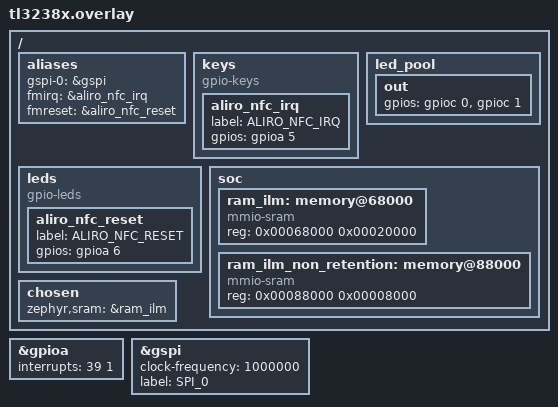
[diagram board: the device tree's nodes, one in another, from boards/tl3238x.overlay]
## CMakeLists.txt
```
#
#    Copyright (c) 2023-2024 Project CHIP Authors
#
#    Licensed under the Apache License, Version 2.0 (the "License");
#    you may not use this file except in compliance with the License.
#    You may obtain a copy of the License at
#
#        http://www.apache.org/licenses/LICENSE-2.0
#
#    Unless required by applicable law or agreed to in writing, software
#    distributed under the License is distributed on an "AS IS" BASIS,
#    WITHOUT WARRANTIES OR CONDITIONS OF ANY KIND, either express or implied.
#    See the License for the specific language governing permissions and
#    limitations under the License.
#

cmake_minimum_required(VERSION 3.20)

if(POLICY CMP0135)
  cmake_policy(SET CMP0135 NEW)
endif()

include(FetchContent)

get_filename_component(CHIP_ROOT ${CMAKE_CURRENT_SOURCE_DIR}/third_party/connectedhomeip REALPATH)
get_filename_component(TELINK_COMMON ${CHIP_ROOT}/examples/platform/telink REALPATH)
get_filename_component(GEN_DIR ${CHIP_ROOT}/zzz_generated/ REALPATH)

include(${TELINK_COMMON}/common.cmake)
include(${CHIP_ROOT}/config/telink/app/enable-gnu-std.cmake)
include(${CHIP_ROOT}/src/app/chip_data_model.cmake)

project(chip-telink-lock-aliro-minimal-example)

set(TELINK_ALIRO_SDK_URL
    "https://doc.telink-semi.cn/Zephyr/binaries/public/aliro/telink-aliro-sdk-latest.tar.gz"
    CACHE STRING "Telink Aliro SDK archive URL")

if(CONFIG_ALIRO_TRANSPORT_NFC)
  if(FETCHCONTENT_SOURCE_DIR_TELINK_ALIRO)
    FetchContent_Declare(telink_aliro
      SOURCE_DIR "${FETCHCONTENT_SOURCE_DIR_TELINK_ALIRO}"
      SOURCE_SUBDIR cmake/zephyr
    )
  else()
    if(NOT TELINK_ALIRO_SDK_URL)
      message(FATAL_ERROR
        "TELINK_ALIRO_SDK_URL is not set. Provide the published SDK URL or "
        "-DFETCHCONTENT_SOURCE_DIR_TELINK_ALIRO=/path/to/telink_aliro."
      )
    endif()

    FetchContent_Declare(telink_aliro
      URL "${TELINK_ALIRO_SDK_URL}"
      TLS_VERIFY TRUE
      SOURCE_SUBDIR cmake/zephyr
    )
  endif()

  FetchContent_MakeAvailable(telink_aliro)
  target_link_libraries(app PRIVATE Telink::Aliro)
endif()

target_include_directories(app PRIVATE
                           include
                           ${GEN_DIR}/app-common
                           ${GEN_DIR}/lock-app
                           ${TELINK_COMMON}/common/include
                           ${TELINK_COMMON}/util/include
                           ${TELINK_COMMON}/app/include
                           ${TELINK_COMMON}/zephyr_ext)

target_sources(app PRIVATE
               src/AppTask.cpp
               src/AliroDelegate.cpp
               src/ZclCallbacks.cpp
               src/LockManager.cpp
               ${TELINK_COMMON}/common/src/mainCommon.cpp
               ${TELINK_COMMON}/common/src/AppTaskCommon.cpp
               ${TELINK_COMMON}/util/src/LEDManager.cpp
               ${TELINK_COMMON}/util/src/ButtonManager.cpp
               ${TELINK_COMMON}/util/src/ThreadUtil.cpp
               ${TELINK_COMMON}/util/src/PWMManager.cpp
               ${TELINK_COMMON}/zephyr_ext/zephyr_key_matrix.c
               ${TELINK_COMMON}/zephyr_ext/zephyr_led_pool.c)

chip_configure_data_model(app
    ZAP_FILE ${CMAKE_CURRENT_SOURCE_DIR}/lock-app-minimal.zap
)

if(CONFIG_BOOTLOADER_MCUBOOT)
  target_sources(app PRIVATE ${TELINK_COMMON}/util/src/OTAUtil.cpp)
endif()

if(CONFIG_MCUMGR_TRANSPORT_BT)
    zephyr_library_link_libraries(MCUBOOT_BOOTUTIL)
    target_sources(app PRIVATE ${TELINK_COMMON}/util/src/DFUOverSMP.cpp)
endif()
```

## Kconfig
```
#
#    Copyright (c) 2023 Project CHIP Authors
#
#    Licensed under the Apache License, Version 2.0 (the "License");
#    you may not use this file except in compliance with the License.
#    You may obtain a copy of the License at
#
#        http://www.apache.org/licenses/LICENSE-2.0
#
#    Unless required by applicable law or agreed to in writing, software
#    distributed under the License is distributed on an "AS IS" BASIS,
#    WITHOUT WARRANTIES OR CONDITIONS OF ANY KIND, either express or implied.
#    See the License for the specific language governing permissions and
#    limitations under the License.
#
mainmenu "Matter Telink Lock Example Application"

config SETTINGS_NVS_NAME_CACHE
    default y

config SETTINGS_NVS_NAME_CACHE_SIZE
    default 256

menu "Aliro NFC configuration"

config ALIRO_TRANSPORT_NFC
    bool "Enable Aliro NFC transport"
    default y

config ALIRO_NFC_POLLER_THREAD_STACK_SIZE
    int "Aliro NFC poller thread stack size"
    depends on ALIRO_TRANSPORT_NFC
    default 4096

config ALIRO_LOG_LEVEL
    int "Aliro protocol log level"
    range 0 4
    default 3
    help
      Keep protocol logging at informational level for normal builds. Level 4
      exposes ephemeral and derived transaction keys and is for controlled
      development only.

config ALIRO_FAST_TRANSACTION
    bool "Enable Aliro expedited transactions"
    default n

config ALIRO_KEYSLOT_CREDENTIALS
    bool "Enable Aliro endpoint key-slot credentials"
    default n

config CLRC663_IC
    bool
    default y
    depends on ALIRO_TRANSPORT_NFC

endmenu

rsource "../../../config/telink/chip-module/Kconfig.defaults"
source "Kconfig.zephyr"
```

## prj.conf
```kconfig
#
#    Copyright (c) 2023-2024 Project CHIP Authors
#
#    Licensed under the Apache License, Version 2.0 (the "License");
#    you may not use this file except in compliance with the License.
#    You may obtain a copy of the License at
#
#        http://www.apache.org/licenses/LICENSE-2.0
#
#    Unless required by applicable law or agreed to in writing, software
#    distributed under the License is distributed on an "AS IS" BASIS,
#    WITHOUT WARRANTIES OR CONDITIONS OF ANY KIND, either express or implied.
#    See the License for the specific language governing permissions and
#    limitations under the License.
#

# This sample uses Kconfig.defaults to set options common for all
# samples. This file should contain only options specific for this sample
# or overrides of default values.

# Enable CHIP
CONFIG_CHIP=y
CONFIG_STD_CPP17=y

# 32774 == 0x8006 (example lock-app)
CONFIG_CHIP_DEVICE_PRODUCT_ID=32774

CONFIG_BT_DEVICE_NAME="TelinkAliro"

# Disable Matter OTA DFU
CONFIG_CHIP_OTA_REQUESTOR=n
CONFIG_CHIP_DEVICE_SOFTWARE_VERSION=1

# Disable CHIP shell support
CONFIG_CHIP_LIB_SHELL=n
CONFIG_CHIP_PERSISTENT_SUBSCRIPTIONS=n
CONFIG_CHIP_MAX_FABRICS=2

# Disable factory data support
CONFIG_CHIP_FACTORY_DATA=n
CONFIG_CHIP_FACTORY_DATA_BUILD=n
CONFIG_CHIP_FACTORY_DATA_MERGE_WITH_FIRMWARE=n

# Telink PM integration is a separate pass from Aliro linkability.
CONFIG_PM=n
CONFIG_CHIP_THREAD_DEVICE_ROLE_END_DEVICE=y

# Aliro release-one transport: NFC with the CLRC663 frontend.
CONFIG_ALIRO_TRANSPORT_NFC=y
CONFIG_ALIRO_NFC_POLLER_THREAD_STACK_SIZE=4096
CONFIG_ALIRO_LOG_LEVEL=3
CONFIG_ALIRO_FAST_TRANSACTION=n
CONFIG_ALIRO_KEYSLOT_CREDENTIALS=n
CONFIG_BT_MAX_CONN=1

# Match the TL3238 production BLE controller sizing. The common defaults on
# this branch otherwise fall through to 712 bytes and overflow in bt_hci_recv().
CONFIG_TL_BLE_CTRL_THREAD_STACK_SIZE=1536

# NFC frontend support used by the Aliro ECP poller.
CONFIG_GPIO=y
CONFIG_SPI=y

# Aliro crypto requirements not already guaranteed by Matter defaults.
CONFIG_MBEDTLS_SHA1=y
CONFIG_MBEDTLS_HMAC_DRBG_ENABLED=y
CONFIG_MBEDTLS_MD=y
CONFIG_MBEDTLS_CIPHER_GCM_ENABLED=y

# Keep Matter's standard Telink malloc arena. Reducing this to 16 KiB exhausts
# the libc heap during Operational Credentials CSR generation.
CONFIG_COMMON_LIBC_MALLOC_ARENA_SIZE=26584
CONFIG_HEAP_MEM_POOL_SIZE=1796

# Probe-only RAM trims. These need product validation before becoming real defaults.
CONFIG_MAIN_STACK_SIZE=3560
CONFIG_SYSTEM_WORKQUEUE_STACK_SIZE=1024

CONFIG_OPENTHREAD_THREAD_STACK_SIZE=2048
CONFIG_OPENTHREAD_NUM_MESSAGE_BUFFERS=32

CONFIG_NET_PKT_RX_COUNT=4
CONFIG_NET_PKT_TX_COUNT=4
CONFIG_NET_BUF_RX_COUNT=8
# A full ecosystem subscription report requires more than eight 128-byte
# fragments. Keep the standard Telink lock-app TX buffer count.
CONFIG_NET_BUF_TX_COUNT=12

CONFIG_NVS_LOOKUP_CACHE_SIZE=128
CONFIG_SETTINGS_NVS_NAME_CACHE_SIZE=64
CONFIG_SETTINGS_NVS_SECTOR_COUNT=2
```

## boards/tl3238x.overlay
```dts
/ {
	aliases {
		gspi-0 = &gspi;
		fmirq = &aliro_nfc_irq;
		fmreset = &aliro_nfc_reset;
	};

	keys {
		compatible = "gpio-keys";

		aliro_nfc_irq: aliro_nfc_irq {
			label = "ALIRO_NFC_IRQ";
			gpios = <&gpioa 5 (GPIO_ACTIVE_HIGH | GPIO_PULL_DOWN)>;
		};
	};

	leds {
		compatible = "gpio-leds";

		aliro_nfc_reset: aliro_nfc_reset {
			label = "ALIRO_NFC_RESET";
			gpios = <&gpioa 6 GPIO_ACTIVE_HIGH>;
		};
	};

	led_pool {
		out {
			gpios = <&gpioc 0 GPIO_ACTIVE_HIGH>,
				<&gpioc 1 GPIO_ACTIVE_HIGH>;
		};
	};
};

&gpioa {
	interrupts = <39 1>;
	status = "okay";
};

&gspi {
	clock-frequency = <1000000>;
	label = "SPI_0";
	status = "okay";
};

/ {
	soc {
		/delete-node/ memory@68000;
		/delete-node/ memory@80000;

		ram_ilm: memory@68000 {
			compatible = "mmio-sram";
			reg = <0x00068000 0x00020000>;
		};

		ram_ilm_non_retention: memory@88000 {
			compatible = "mmio-sram";
			reg = <0x00088000 0x00008000>;
		};
	};

	chosen {
		zephyr,sram = &ram_ilm;
	};
};
```

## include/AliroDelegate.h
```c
/*
 *
 *    Copyright (c) 2026 Project CHIP Authors
 *    All rights reserved.
 *
 *    Licensed under the Apache License, Version 2.0 (the "License");
 *    you may not use this file except in compliance with the License.
 *    You may obtain a copy of the License at
 *
 *        http://www.apache.org/licenses/LICENSE-2.0
 *
 *    Unless required by applicable law or agreed to in writing, software
 *    distributed under the License is distributed on an "AS IS" BASIS,
 *    WITHOUT WARRANTIES OR CONDITIONS OF ANY KIND, either express or implied.
 *    See the License for the specific language governing permissions and
 *    limitations under the License.
 */

#pragma once

#include <AppConfig.h>
#include <app/clusters/door-lock-server/door-lock-delegate.h>
#include <app/clusters/door-lock-server/door-lock-server.h>

class AliroDelegate : public chip::app::Clusters::DoorLock::Delegate
{
public:
    static AliroDelegate & GetInstance() { return sInstance; }

    AliroDelegate(const AliroDelegate &)             = delete;
    AliroDelegate & operator=(const AliroDelegate &) = delete;

    // DoorLock::Delegate interface
    CHIP_ERROR GetAliroReaderVerificationKey(chip::MutableByteSpan & verificationKey) override;
    CHIP_ERROR GetAliroReaderGroupIdentifier(chip::MutableByteSpan & groupIdentifier) override;
    CHIP_ERROR GetAliroReaderGroupSubIdentifier(chip::MutableByteSpan & groupSubIdentifier) override;
    CHIP_ERROR GetAliroExpeditedTransactionSupportedProtocolVersionAtIndex(size_t index,
                                                                           chip::MutableByteSpan & protocolVersion) override;
    CHIP_ERROR GetAliroGroupResolvingKey(chip::MutableByteSpan & groupResolvingKey) override;
    CHIP_ERROR GetAliroSupportedBLEUWBProtocolVersionAtIndex(size_t index, chip::MutableByteSpan & protocolVersion) override;
    uint8_t GetAliroBLEAdvertisingVersion() override;
    uint16_t GetNumberOfAliroCredentialIssuerKeysSupported() override;
    uint16_t GetNumberOfAliroEndpointKeysSupported() override;
    CHIP_ERROR SetAliroReaderConfig(const chip::ByteSpan & signingKey, const chip::ByteSpan & verificationKey,
                                    const chip::ByteSpan & groupIdentifier,
                                    const chip::Optional<chip::ByteSpan> & groupResolvingKey) override;
    CHIP_ERROR ClearAliroReaderConfig() override;

    // Aliro credential storage - called from LockManager
    static bool IsAliroCredentialType(CredentialTypeEnum type);
    bool GetCredential(uint16_t index, CredentialTypeEnum type, EmberAfPluginDoorLockCredentialInfo & out);
    bool SetCredential(uint16_t index, chip::FabricIndex creator, chip::FabricIndex modifier, DlCredentialStatus status,
                       CredentialTypeEnum type, const chip::ByteSpan & data);
    bool FindEndpointKey(const chip::ByteSpan & key, CredentialTypeEnum & type, uint16_t & index) const;

private:
    AliroDelegate() = default;

    CHIP_ERROR CopyProtocolVersionIntoSpan(uint16_t protocolVersionValue, chip::MutableByteSpan & protocolVersion);

    // Aliro provisioning state
    uint8_t mAliroReaderVerificationKey[chip::app::Clusters::DoorLock::kAliroReaderVerificationKeySize];
    uint8_t mAliroReaderGroupIdentifier[chip::app::Clusters::DoorLock::kAliroReaderGroupIdentifierSize];
    uint8_t mAliroReaderGroupSubIdentifier[chip::app::Clusters::DoorLock::kAliroReaderGroupSubIdentifierSize];
    uint8_t mAliroGroupResolvingKey[chip::app::Clusters::DoorLock::kAliroGroupResolvingKeySize];
    bool mAliroStateInitialized = false;

    // Aliro credential storage (in-memory; Aliro keys are not persisted to NVM)
    static constexpr size_t kAliroCredentialMaxSize = 65;

    struct CredentialSlot
    {
        DlCredentialStatus status             = DlCredentialStatus::kAvailable;
        CredentialTypeEnum type               = CredentialTypeEnum::kUnknownEnumValue;
        uint16_t index                        = 0;
        chip::FabricIndex createdBy           = 0;
        chip::FabricIndex lastModifiedBy      = 0;
        size_t dataSize                       = 0;
        uint8_t data[kAliroCredentialMaxSize] = { 0 };
    };

    static bool IsEndpointCredentialType(CredentialTypeEnum type);
    CredentialSlot * FindSlot(uint16_t index, CredentialTypeEnum type);
    const CredentialSlot * FindSlot(uint16_t index, CredentialTypeEnum type) const;
    CredentialSlot * FindAvailableEndpointSlot();
    size_t SlotCountForType(CredentialTypeEnum type) const;

    CredentialSlot mIssuerKeys[APP_MAX_ALIRO_ISSUER_KEYS];
    CredentialSlot mEndpointKeys[APP_MAX_ALIRO_ENDPOINT_KEYS];

    static AliroDelegate sInstance;
};
```

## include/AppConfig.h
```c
/*
 *
 *    Copyright (c) 2023 Project CHIP Authors
 *    All rights reserved.
 *
 *    Licensed under the Apache License, Version 2.0 (the "License");
 *    you may not use this file except in compliance with the License.
 *    You may obtain a copy of the License at
 *
 *        http://www.apache.org/licenses/LICENSE-2.0
 *
 *    Unless required by applicable law or agreed to in writing, software
 *    distributed under the License is distributed on an "AS IS" BASIS,
 *    WITHOUT WARRANTIES OR CONDITIONS OF ANY KIND, either express or implied.
 *    See the License for the specific language governing permissions and
 *    limitations under the License.
 */

#pragma once

// ---- Lock Example App Config ----

#define LOCK_MANAGER_ACTUATOR_MOVEMENT_TIME_MS 2000

#define APP_MAX_USERS 6
#define APP_MAX_CREDENTIALS_PER_USER 6
#define APP_MAX_PIN_CREDENTIALS 2
#define APP_MAX_ALIRO_ISSUER_KEYS 3
#define APP_MAX_ALIRO_ENDPOINT_KEYS 6

#define APP_SET_DEVICE_INFO_PROVIDER 1
#define APP_SET_NETWORK_COMM_ENDPOINT_SEC 0
```

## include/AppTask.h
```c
/*
 *
 *    Copyright (c) 2023 Project CHIP Authors
 *    All rights reserved.
 *
 *    Licensed under the Apache License, Version 2.0 (the "License");
 *    you may not use this file except in compliance with the License.
 *    You may obtain a copy of the License at
 *
 *        http://www.apache.org/licenses/LICENSE-2.0
 *
 *    Unless required by applicable law or agreed to in writing, software
 *    distributed under the License is distributed on an "AS IS" BASIS,
 *    WITHOUT WARRANTIES OR CONDITIONS OF ANY KIND, either express or implied.
 *    See the License for the specific language governing permissions and
 *    limitations under the License.
 */

#pragma once

#include "AppConfig.h"
#include "AppTaskCommon.h"
#include "LockManager.h"

#include <telink_aliro/telink_aliro.h>

#define APP_ERROR_EVENT_QUEUE_FAILED CHIP_APPLICATION_ERROR(0x01)
#define APP_ERROR_CREATE_TASK_FAILED CHIP_APPLICATION_ERROR(0x02)
#define APP_ERROR_UNHANDLED_EVENT CHIP_APPLICATION_ERROR(0x03)
#define APP_ERROR_CREATE_TIMER_FAILED CHIP_APPLICATION_ERROR(0x04)
#define APP_ERROR_START_TIMER_FAILED CHIP_APPLICATION_ERROR(0x05)
#define APP_ERROR_STOP_TIMER_FAILED CHIP_APPLICATION_ERROR(0x06)
#define APP_ERROR_ALLOCATION_FAILED CHIP_APPLICATION_ERROR(0x07)

class AppTask : public AppTaskCommon
{
private:
    friend AppTask & GetAppTask(void);
    friend class AppTaskCommon;

    CHIP_ERROR Init(void);
    void LinkButtons(ButtonManager & buttonManager);
    void LinkLeds(LedManager & ledManager);

    static void LockActionEventHandler(AppEvent * event);
    static void AliroLockActionEventHandler(AppEvent * event);
    static int GetAliroLockState(enum telink_aliro_lock_state * state, void * context);
    static int RequestAliroLockState(enum telink_aliro_lock_state state, void * context);
    static int AuthorizeAliroEndpoint(const uint8_t * publicKey, size_t publicKeySize, void * context);
    static void LockStateChanged(LockManager::State_t state);
    static AppTask sAppTask;
};

inline AppTask & GetAppTask(void)
{
    return AppTask::sAppTask;
}
```

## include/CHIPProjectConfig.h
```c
/*
 *
 *    Copyright (c) 2023 Project CHIP Authors
 *    All rights reserved.
 *
 *    Licensed under the Apache License, Version 2.0 (the "License");
 *    you may not use this file except in compliance with the License.
 *    You may obtain a copy of the License at
 *
 *        http://www.apache.org/licenses/LICENSE-2.0
 *
 *    Unless required by applicable law or agreed to in writing, software
 *    distributed under the License is distributed on an "AS IS" BASIS,
 *    WITHOUT WARRANTIES OR CONDITIONS OF ANY KIND, either express or implied.
 *    See the License for the specific language governing permissions and
 *    limitations under the License.
 */

/**
 *    @file
 *          Example project configuration file for CHIP.
 *
 *          This is a place to put application or project-specific overrides
 *          to the default configuration values for general CHIP features.
 *
 */

#pragma once

// Use a default pairing code if one hasn't been provisioned in flash.
#define CHIP_DEVICE_CONFIG_USE_TEST_SETUP_PIN_CODE 20202021
#define CHIP_DEVICE_CONFIG_USE_TEST_SETUP_DISCRIMINATOR 0xF00

// Enable `Extension` attribute of ACL Cluster as required by door locks
#define CHIP_CONFIG_ENABLE_ACL_EXTENSIONS 1

// Functional two-fabric prototype profile. Certification will require at least
// five fabrics and another resource pass.
#define CHIP_CONFIG_MAX_EXCHANGE_CONTEXTS 8
#define CHIP_CONFIG_MAX_UNSOLICITED_MESSAGE_HANDLERS 8
#define CHIP_CONFIG_MAX_GROUP_DATA_PEERS 5
#define CHIP_CONFIG_EXAMPLE_ACCESS_CONTROL_MAX_ENTRIES_PER_FABRIC 4
#define CHIP_IM_MAX_NUM_COMMAND_HANDLER 2
#define CHIP_IM_MAX_NUM_WRITE_HANDLER 2
#define CHIP_IM_MAX_NUM_WRITE_CLIENT 1
#define CHIP_CONFIG_DEVICE_MAX_ACTIVE_DEVICES 2
```

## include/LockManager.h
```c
/*
 *
 *    Copyright (c) 2023-2026 Project CHIP Authors
 *    All rights reserved.
 *
 *    Licensed under the Apache License, Version 2.0 (the "License");
 *    you may not use this file except in compliance with the License.
 *    You may obtain a copy of the License at
 *
 *        http://www.apache.org/licenses/LICENSE-2.0
 *
 *    Unless required by applicable law or agreed to in writing, software
 *    distributed under the License is distributed on an "AS IS" BASIS,
 *    WITHOUT WARRANTIES OR CONDITIONS OF ANY KIND, either express or implied.
 *    See the License for the specific language governing permissions and
 *    limitations under the License.
 */

#pragma once

#include <AppConfig.h>
#include <AppEventCommon.h>
#include <app/clusters/door-lock-server/door-lock-server.h>
#include <app/data-model/Nullable.h>
#include <lib/core/CHIPError.h>
#include <zephyr/kernel.h>

class LockManager
{
public:
    using CredentialRuleEnum = chip::app::Clusters::DoorLock::CredentialRuleEnum;
    using CredentialStruct   = chip::app::Clusters::DoorLock::Structs::CredentialStruct::Type;
    using CredentialTypeEnum = chip::app::Clusters::DoorLock::CredentialTypeEnum;
    using DlCredentialStatus = ::DlCredentialStatus;
    using DlLockState        = chip::app::Clusters::DoorLock::DlLockState;
    using OperationErrorEnum = chip::app::Clusters::DoorLock::OperationErrorEnum;
    using OperationSource    = chip::app::Clusters::DoorLock::OperationSourceEnum;
    using UserStatusEnum     = chip::app::Clusters::DoorLock::UserStatusEnum;
    using UserTypeEnum       = chip::app::Clusters::DoorLock::UserTypeEnum;

    enum Action_t
    {
        LOCK_ACTION = 0,
        UNLOCK_ACTION,
        INVALID_ACTION
    };

    enum State_t
    {
        kState_LockInitiated = 0,
        kState_LockCompleted,
        kState_UnlockInitiated,
        kState_UnlockCompleted,
        kState_NotFulyLocked
    };

    using StateChangeCallback = void (*)(State_t);

    CHIP_ERROR Init(chip::app::DataModel::Nullable<DlLockState> state, StateChangeCallback callback);

    bool LockAction(int32_t appSource, Action_t action, OperationSource source, chip::EndpointId endpointId);
    bool LockAction(int32_t appSource, Action_t action, OperationSource source, chip::EndpointId endpointId,
                    OperationErrorEnum & err,
                    const chip::app::DataModel::Nullable<chip::FabricIndex> & fabricIdx = chip::app::DataModel::NullNullable,
                    const chip::app::DataModel::Nullable<chip::NodeId> & nodeId         = chip::app::DataModel::NullNullable,
                    const chip::Optional<chip::ByteSpan> & pinCode                      = chip::NullOptional);

    bool IsLocked() const { return mState == kState_LockCompleted; }
    State_t getLockState() const { return mState; }

    bool GetUser(chip::EndpointId endpointId, uint16_t userIndex, EmberAfPluginDoorLockUserInfo & user);
    bool SetUser(chip::EndpointId endpointId, uint16_t userIndex, chip::FabricIndex creator, chip::FabricIndex modifier,
                 const chip::CharSpan & userName, uint32_t uniqueId, UserStatusEnum userStatus, UserTypeEnum userType,
                 CredentialRuleEnum credentialRule, const CredentialStruct * credentials, size_t totalCredentials);

    bool GetCredential(chip::EndpointId endpointId, uint16_t credentialIndex, CredentialTypeEnum credentialType,
                       EmberAfPluginDoorLockCredentialInfo & credential);
    bool SetCredential(chip::EndpointId endpointId, uint16_t credentialIndex, chip::FabricIndex creator, chip::FabricIndex modifier,
                       DlCredentialStatus credentialStatus, CredentialTypeEnum credentialType,
                       const chip::ByteSpan & credentialData);
    bool ValidateAliroEndpointKey(const chip::ByteSpan & key) const;

private:
    struct UserSlot
    {
        char name[DOOR_LOCK_USER_NAME_BUFFER_SIZE]                 = {};
        CredentialStruct credentials[APP_MAX_CREDENTIALS_PER_USER] = {};
        size_t credentialCount                                     = 0;
        uint32_t uniqueId                                          = 0;
        UserStatusEnum status                                      = UserStatusEnum::kAvailable;
        UserTypeEnum type                                          = UserTypeEnum::kUnrestrictedUser;
        CredentialRuleEnum credentialRule                          = CredentialRuleEnum::kSingle;
        chip::FabricIndex createdBy                                = 0;
        chip::FabricIndex lastModifiedBy                           = 0;
    };

    struct PinCredentialSlot
    {
        DlCredentialStatus status        = DlCredentialStatus::kAvailable;
        chip::FabricIndex createdBy      = 0;
        chip::FabricIndex lastModifiedBy = 0;
        size_t dataSize                  = 0;
        uint8_t data[8]                  = {};
    };

    friend LockManager & LockMgr();

    bool StartAction(Action_t action, OperationSource source, chip::EndpointId endpointId,
                     const chip::app::DataModel::Nullable<chip::FabricIndex> & fabricIdx,
                     const chip::app::DataModel::Nullable<chip::NodeId> & nodeId);
    static void ActuatorTimerEventHandler(k_timer * timer);
    static void ActuatorAppEventHandler(const AppEvent & event);

    static LockManager sLock;
    State_t mState                                             = kState_NotFulyLocked;
    StateChangeCallback mStateChangeCallback                   = nullptr;
    k_timer mActuatorTimer                                     = {};
    UserSlot mUsers[APP_MAX_USERS]                             = {};
    PinCredentialSlot mPinCredentials[APP_MAX_PIN_CREDENTIALS] = {};
};

inline LockManager & LockMgr()
{
    return LockManager::sLock;
}
```

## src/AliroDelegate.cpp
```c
/*
 *
 *    Copyright (c) 2026 Project CHIP Authors
 *    All rights reserved.
 *
 *    Licensed under the Apache License, Version 2.0 (the "License");
 *    you may not use this file except in compliance with the License.
 *    You may obtain a copy of the License at
 *
 *        http://www.apache.org/licenses/LICENSE-2.0
 *
 *    Unless required by applicable law or agreed to in writing, software
 *    distributed under the License is distributed on an "AS IS" BASIS,
 *    WITHOUT WARRANTIES OR CONDITIONS OF ANY KIND, either express or implied.
 *    See the License for the specific language governing permissions and
 *    limitations under the License.
 */

#include "AliroDelegate.h"

#include <crypto/CHIPCryptoPAL.h>
#include <lib/core/CHIPEncoding.h>
#include <lib/support/Span.h>
#include <lib/support/logging/CHIPLogging.h>
#include <telink_aliro/telink_aliro.h>

using namespace chip;
using namespace chip::app::Clusters::DoorLock;

AliroDelegate AliroDelegate::sInstance;

// ---------------------------------------------------------------------------
// DoorLock::Delegate - Aliro provisioning attributes
// ---------------------------------------------------------------------------

CHIP_ERROR AliroDelegate::GetAliroReaderVerificationKey(MutableByteSpan & verificationKey)
{
    ChipLogProgress(Zcl, "[Aliro] Read ReaderVerificationKey (configured=%u)", mAliroStateInitialized);

    if (!mAliroStateInitialized)
    {
        verificationKey.reduce_size(0);
        return CHIP_NO_ERROR;
    }

    return CopySpanToMutableSpan(ByteSpan(mAliroReaderVerificationKey), verificationKey);
}

CHIP_ERROR AliroDelegate::GetAliroReaderGroupIdentifier(MutableByteSpan & groupIdentifier)
{
    ChipLogProgress(Zcl, "[Aliro] Read ReaderGroupIdentifier (configured=%u)", mAliroStateInitialized);

    if (!mAliroStateInitialized)
    {
        groupIdentifier.reduce_size(0);
        return CHIP_NO_ERROR;
    }

    return CopySpanToMutableSpan(ByteSpan(mAliroReaderGroupIdentifier), groupIdentifier);
}

CHIP_ERROR AliroDelegate::GetAliroReaderGroupSubIdentifier(MutableByteSpan & groupSubIdentifier)
{
    ChipLogProgress(Zcl, "[Aliro] Read ReaderGroupSubIdentifier (configured=%u)", mAliroStateInitialized);

    if (!mAliroStateInitialized)
    {
        groupSubIdentifier.reduce_size(0);
        return CHIP_NO_ERROR;
    }

    return CopySpanToMutableSpan(ByteSpan(mAliroReaderGroupSubIdentifier), groupSubIdentifier);
}

CHIP_ERROR AliroDelegate::CopyProtocolVersionIntoSpan(uint16_t protocolVersionValue, MutableByteSpan & protocolVersion)
{
    static_assert(sizeof(protocolVersionValue) == kAliroProtocolVersionSize);

    if (protocolVersion.size() < kAliroProtocolVersionSize)
    {
        return CHIP_ERROR_INVALID_ARGUMENT;
    }

    // Per Aliro spec, protocol version encoding is big-endian.
    Encoding::BigEndian::Put16(protocolVersion.data(), protocolVersionValue);
    protocolVersion.reduce_size(kAliroProtocolVersionSize);
    return CHIP_NO_ERROR;
}

CHIP_ERROR AliroDelegate::GetAliroExpeditedTransactionSupportedProtocolVersionAtIndex(size_t index,
                                                                                      MutableByteSpan & protocolVersion)
{
    ChipLogProgress(Zcl, "[Aliro] Read ExpeditedProtocolVersion (index=%u)", static_cast<unsigned>(index));

    // Only claim support for the one known protocol version for now: 0x0100.
    constexpr uint16_t knownProtocolVersion = 0x0100;

    if (index > 0)
    {
        return CHIP_ERROR_PROVIDER_LIST_EXHAUSTED;
    }

    return CopyProtocolVersionIntoSpan(knownProtocolVersion, protocolVersion);
}

CHIP_ERROR AliroDelegate::GetAliroGroupResolvingKey(MutableByteSpan & groupResolvingKey)
{
    ChipLogProgress(Zcl, "[Aliro] Read GroupResolvingKey (configured=%u)", mAliroStateInitialized);

    if (!mAliroStateInitialized)
    {
        groupResolvingKey.reduce_size(0);
        return CHIP_NO_ERROR;
    }

    return CopySpanToMutableSpan(ByteSpan(mAliroGroupResolvingKey), groupResolvingKey);
}

CHIP_ERROR AliroDelegate::GetAliroSupportedBLEUWBProtocolVersionAtIndex(size_t index, MutableByteSpan & protocolVersion)
{
    ChipLogProgress(Zcl, "[Aliro] Read BLEUWBProtocolVersion (index=%u)", static_cast<unsigned>(index));

    (void) index;
    (void) protocolVersion;
    return CHIP_ERROR_PROVIDER_LIST_EXHAUSTED;
}

uint8_t AliroDelegate::GetAliroBLEAdvertisingVersion()
{
    ChipLogProgress(Zcl, "[Aliro] Read BLEAdvertisingVersion");

    // For now the only defined value of the BLE advertising version for Aliro is 0.
    return 0;
}

uint16_t AliroDelegate::GetNumberOfAliroCredentialIssuerKeysSupported()
{
    ChipLogProgress(Zcl, "[Aliro] Read NumberOfCredentialIssuerKeysSupported");
    return APP_MAX_ALIRO_ISSUER_KEYS;
}

uint16_t AliroDelegate::GetNumberOfAliroEndpointKeysSupported()
{
    ChipLogProgress(Zcl, "[Aliro] Read NumberOfEndpointKeysSupported");
    return APP_MAX_ALIRO_ENDPOINT_KEYS;
}

CHIP_ERROR AliroDelegate::SetAliroReaderConfig(const ByteSpan & signingKey, const ByteSpan & verificationKey,
                                               const ByteSpan & groupIdentifier, const Optional<ByteSpan> & groupResolvingKey)
{
    uint8_t groupSubIdentifier[sizeof(mAliroReaderGroupSubIdentifier)];

    VerifyOrReturnError(verificationKey.size() == sizeof(mAliroReaderVerificationKey), CHIP_ERROR_INVALID_ARGUMENT);
    VerifyOrReturnError(groupIdentifier.size() == sizeof(mAliroReaderGroupIdentifier), CHIP_ERROR_INVALID_ARGUMENT);

    if (groupResolvingKey.HasValue())
    {
        VerifyOrReturnError(groupResolvingKey.Value().size() == sizeof(mAliroGroupResolvingKey), CHIP_ERROR_INVALID_ARGUMENT);
    }

    ReturnErrorOnFailure(Crypto::DRBG_get_bytes(groupSubIdentifier, sizeof(groupSubIdentifier)));

    int err = telink_aliro_nfc_set_reader_config(signingKey.data(), signingKey.size(), verificationKey.data(),
                                                 verificationKey.size(), groupIdentifier.data(), groupIdentifier.size(),
                                                 groupSubIdentifier, sizeof(groupSubIdentifier));
    VerifyOrReturnError(err == 0, CHIP_ERROR_INTERNAL,
                        ChipLogError(Zcl, "Unable to apply Aliro NFC reader configuration: %d", err));

    memcpy(mAliroReaderVerificationKey, verificationKey.data(), sizeof(mAliroReaderVerificationKey));
    memcpy(mAliroReaderGroupIdentifier, groupIdentifier.data(), sizeof(mAliroReaderGroupIdentifier));
    memcpy(mAliroReaderGroupSubIdentifier, groupSubIdentifier, sizeof(mAliroReaderGroupSubIdentifier));

    if (groupResolvingKey.HasValue())
    {
        memcpy(mAliroGroupResolvingKey, groupResolvingKey.Value().data(), sizeof(mAliroGroupResolvingKey));
    }

    mAliroStateInitialized = true;
    return CHIP_NO_ERROR;
}

CHIP_ERROR AliroDelegate::ClearAliroReaderConfig()
{
    int err = telink_aliro_nfc_clear_reader_config();
    VerifyOrReturnError(err == 0, CHIP_ERROR_INTERNAL,
                        ChipLogError(Zcl, "Unable to clear Aliro NFC reader configuration: %d", err));

    memset(mAliroReaderVerificationKey, 0, sizeof(mAliroReaderVerificationKey));
    memset(mAliroReaderGroupIdentifier, 0, sizeof(mAliroReaderGroupIdentifier));
    memset(mAliroReaderGroupSubIdentifier, 0, sizeof(mAliroReaderGroupSubIdentifier));
    memset(mAliroGroupResolvingKey, 0, sizeof(mAliroGroupResolvingKey));
    mAliroStateInitialized = false;
    return CHIP_NO_ERROR;
}

// ---------------------------------------------------------------------------
// Aliro credential storage
// ---------------------------------------------------------------------------

/* static */ bool AliroDelegate::IsAliroCredentialType(CredentialTypeEnum type)
{
    switch (type)
    {
    case CredentialTypeEnum::kAliroCredentialIssuerKey:
    case CredentialTypeEnum::kAliroEvictableEndpointKey:
    case CredentialTypeEnum::kAliroNonEvictableEndpointKey:
        return true;
    default:
        return false;
    }
}

/* static */ bool AliroDelegate::IsEndpointCredentialType(CredentialTypeEnum type)
{
    return type == CredentialTypeEnum::kAliroEvictableEndpointKey ||
        type == CredentialTypeEnum::kAliroNonEvictableEndpointKey;
}

AliroDelegate::CredentialSlot * AliroDelegate::FindSlot(uint16_t index, CredentialTypeEnum type)
{
    if (type == CredentialTypeEnum::kAliroCredentialIssuerKey)
    {
        return index > 0 && index <= APP_MAX_ALIRO_ISSUER_KEYS ? &mIssuerKeys[index - 1] : nullptr;
    }

    VerifyOrReturnValue(IsEndpointCredentialType(type), nullptr);
    for (auto & slot : mEndpointKeys)
    {
        if (slot.status != DlCredentialStatus::kAvailable && slot.type == type && slot.index == index)
        {
            return &slot;
        }
    }

    return nullptr;
}

const AliroDelegate::CredentialSlot * AliroDelegate::FindSlot(uint16_t index, CredentialTypeEnum type) const
{
    return const_cast<AliroDelegate *>(this)->FindSlot(index, type);
}

AliroDelegate::CredentialSlot * AliroDelegate::FindAvailableEndpointSlot()
{
    for (auto & slot : mEndpointKeys)
    {
        if (slot.status == DlCredentialStatus::kAvailable)
        {
            return &slot;
        }
    }

    return nullptr;
}

size_t AliroDelegate::SlotCountForType(CredentialTypeEnum type) const
{
    return type == CredentialTypeEnum::kAliroCredentialIssuerKey ? APP_MAX_ALIRO_ISSUER_KEYS
        : (type == CredentialTypeEnum::kAliroEvictableEndpointKey || type == CredentialTypeEnum::kAliroNonEvictableEndpointKey)
        ? APP_MAX_ALIRO_ENDPOINT_KEYS
        : 0;
}

bool AliroDelegate::GetCredential(uint16_t index, CredentialTypeEnum type, EmberAfPluginDoorLockCredentialInfo & out)
{
    VerifyOrReturnValue(index > 0 && index <= SlotCountForType(type), false);

    const CredentialSlot * slot = FindSlot(index, type);

    out.status             = slot != nullptr ? slot->status : DlCredentialStatus::kAvailable;
    out.credentialType     = type;
    out.createdBy          = slot != nullptr ? slot->createdBy : 0;
    out.lastModifiedBy     = slot != nullptr ? slot->lastModifiedBy : 0;
    out.creationSource     = DlAssetSource::kMatterIM;
    out.modificationSource = DlAssetSource::kMatterIM;
    out.credentialData     = slot != nullptr ? chip::ByteSpan{ slot->data, slot->dataSize } : chip::ByteSpan{};

    ChipLogProgress(Zcl, "AliroDelegate::GetCredential [type=%u,index=%u,status=%d]", to_underlying(type), index,
                    static_cast<int>(out.status));

    return true;
}

bool AliroDelegate::SetCredential(uint16_t index, chip::FabricIndex creator, chip::FabricIndex modifier, DlCredentialStatus status,
                                  CredentialTypeEnum type, const chip::ByteSpan & data)
{
    VerifyOrReturnValue(index > 0 && index <= SlotCountForType(type), false);
    CredentialSlot * slot = FindSlot(index, type);

    if (status == DlCredentialStatus::kAvailable)
    {
        if (slot != nullptr)
        {
            memset(slot->data, 0, sizeof(slot->data));
            *slot = CredentialSlot{};
        }
        return true;
    }

    VerifyOrReturnValue(data.size() <= kAliroCredentialMaxSize, false);

    if (slot == nullptr && IsEndpointCredentialType(type))
    {
        slot = FindAvailableEndpointSlot();
    }
    VerifyOrReturnValue(slot != nullptr, false);

    memset(slot->data, 0, sizeof(slot->data));
    memcpy(slot->data, data.data(), data.size());
    slot->dataSize       = data.size();
    slot->status         = status;
    slot->type           = type;
    slot->index          = index;
    slot->createdBy      = creator;
    slot->lastModifiedBy = modifier;

    ChipLogProgress(Zcl, "AliroDelegate::SetCredential [type=%u,index=%u,dataSize=%u]", to_underlying(type), index,
                    static_cast<unsigned int>(data.size()));

    return true;
}

bool AliroDelegate::FindEndpointKey(const chip::ByteSpan & key, CredentialTypeEnum & type, uint16_t & index) const
{
    VerifyOrReturnValue(key.size() == kAliroCredentialMaxSize, false);

    for (const auto & slot : mEndpointKeys)
    {
        if (slot.status != DlCredentialStatus::kAvailable && slot.dataSize == key.size() &&
            memcmp(slot.data, key.data(), key.size()) == 0)
        {
            type  = slot.type;
            index = slot.index;
            return true;
        }
    }

    return false;
}
```

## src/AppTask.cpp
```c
/*
 *
 *    Copyright (c) 2023-2024 Project CHIP Authors
 *    All rights reserved.
 *
 *    Licensed under the Apache License, Version 2.0 (the "License");
 *    you may not use this file except in compliance with the License.
 *    You may obtain a copy of the License at
 *
 *        http://www.apache.org/licenses/LICENSE-2.0
 *
 *    Unless required by applicable law or agreed to in writing, software
 *    distributed under the License is distributed on an "AS IS" BASIS,
 *    WITHOUT WARRANTIES OR CONDITIONS OF ANY KIND, either express or implied.
 *    See the License for the specific language governing permissions and
 *    limitations under the License.
 */

#include "AppTask.h"
#include "AliroDelegate.h"
#include "ButtonManager.h"
#include "LEDManager.h"
#include <LockManager.h>
#include <app-common/zap-generated/attributes/Accessors.h>
#include <app/data-model/Nullable.h>
#include <errno.h>

LOG_MODULE_DECLARE(app, CONFIG_CHIP_APP_LOG_LEVEL);

using namespace ::chip::app::Clusters::DoorLock;
using namespace chip;
using namespace chip::app;
using namespace ::chip::DeviceLayer;
using namespace ::chip::DeviceLayer::Internal;

AppTask AppTask::sAppTask;

CHIP_ERROR AppTask::Init(void)
{
    SetExampleButtonCallbacks(LockActionEventHandler);
    ReturnErrorOnFailure(InitCommonParts());

    LedManager::getInstance().setLed(LedManager::EAppLed_App0, LockMgr().IsLocked());

    chip::app::DataModel::Nullable<chip::app::Clusters::DoorLock::DlLockState> state;
    chip::EndpointId endpointId{ kExampleEndpointId };
    chip::DeviceLayer::PlatformMgr().LockChipStack();
    chip::app::Clusters::DoorLock::Attributes::LockState::Get(endpointId, state);

    chip::DeviceLayer::PlatformMgr().UnlockChipStack();

    CHIP_ERROR err = LockMgr().Init(state, LockStateChanged);

    if (err != CHIP_NO_ERROR)
    {
        LOG_ERR("LockMgr().Init() failed");
        return err;
    }

    // Register a Door Lock delegate to handle Aliro provisioning attributes/commands.
    ReturnErrorOnFailure(DoorLockServer::Instance().SetDelegate(kExampleEndpointId, &AliroDelegate::GetInstance()));

    telink_aliro_nfc_callbacks aliroCallbacks = {};
    aliroCallbacks.get_lock_state             = GetAliroLockState;
    aliroCallbacks.request_lock_state         = RequestAliroLockState;
    aliroCallbacks.authorize_endpoint         = AuthorizeAliroEndpoint;

    if (telink_aliro_nfc_init(&aliroCallbacks) != 0)
    {
        LOG_ERR("Aliro NFC initialization failed");
        return CHIP_ERROR_INTERNAL;
    }

    return CHIP_NO_ERROR;
}

int AppTask::GetAliroLockState(enum telink_aliro_lock_state * state, void * context)
{
    (void) context;

    if (state == nullptr)
    {
        return -EINVAL;
    }

    switch (LockMgr().getLockState())
    {
    case LockManager::kState_LockCompleted:
        *state = TELINK_ALIRO_LOCK_STATE_SECURED;
        break;
    case LockManager::kState_UnlockCompleted:
        *state = TELINK_ALIRO_LOCK_STATE_UNSECURED;
        break;
    case LockManager::kState_LockInitiated:
        *state = TELINK_ALIRO_LOCK_STATE_BUSY_SECURED;
        break;
    case LockManager::kState_UnlockInitiated:
        *state = TELINK_ALIRO_LOCK_STATE_BUSY_UNSECURED;
        break;
    default:
        *state = TELINK_ALIRO_LOCK_STATE_JAMMED;
        break;
    }

    return 0;
}

int AppTask::RequestAliroLockState(enum telink_aliro_lock_state state, void * context)
{
    (void) context;

    if (state != TELINK_ALIRO_LOCK_STATE_SECURED && state != TELINK_ALIRO_LOCK_STATE_UNSECURED)
    {
        return -ENOTSUP;
    }

    AppEvent event           = {};
    event.Type               = AppEvent::kEventType_DeviceAction;
    event.DeviceEvent.Action = static_cast<uint8_t>(state);
    event.Handler            = AliroLockActionEventHandler;
    GetAppTask().PostEvent(&event);
    return 0;
}

int AppTask::AuthorizeAliroEndpoint(const uint8_t * publicKey, size_t publicKeySize, void * context)
{
    (void) context;

    if (publicKey == nullptr)
    {
        return -EINVAL;
    }

    chip::DeviceLayer::PlatformMgr().LockChipStack();
    const bool authorized = LockMgr().ValidateAliroEndpointKey(chip::ByteSpan(publicKey, publicKeySize));
    chip::DeviceLayer::PlatformMgr().UnlockChipStack();

    ChipLogProgress(Zcl, "[Aliro] Authenticated endpoint %s", authorized ? "accepted" : "rejected");
    return authorized ? 0 : -EACCES;
}

void AppTask::AliroLockActionEventHandler(AppEvent * event)
{
    if (event == nullptr)
    {
        return;
    }

    LockManager::Action_t action;
    switch (event->DeviceEvent.Action)
    {
    case TELINK_ALIRO_LOCK_STATE_SECURED:
        action = LockManager::LOCK_ACTION;
        break;
    case TELINK_ALIRO_LOCK_STATE_UNSECURED:
        action = LockManager::UNLOCK_ACTION;
        break;
    default:
        return;
    }

    if (!LockMgr().LockAction(AppEvent::kEventType_DeviceAction, action, LockManager::OperationSource::kAliro, kExampleEndpointId))
    {
        LOG_ERR("Aliro lock action failed");
    }
}

/* This is a button handler only */
void AppTask::LockActionEventHandler(AppEvent * aEvent)
{
    switch (LockMgr().getLockState())
    {
    case LockManager::kState_NotFulyLocked:
    case LockManager::kState_LockCompleted:
        LockMgr().LockAction(AppEvent::kEventType_DeviceAction, LockManager::UNLOCK_ACTION, LockManager::OperationSource::kButton,
                             kExampleEndpointId);
        break;
    case LockManager::kState_UnlockCompleted:
        LockMgr().LockAction(AppEvent::kEventType_DeviceAction, LockManager::LOCK_ACTION, LockManager::OperationSource::kButton,
                             kExampleEndpointId);
        break;
    default:
        LOG_INF("Lock is in intermediate state, ignoring button");
        break;
    }
}

void AppTask::LockStateChanged(LockManager::State_t state)
{
    switch (state)
    {
    case LockManager::State_t::kState_LockInitiated:
        LOG_INF("Callback: Lock action initiated");
        LedManager::getInstance().setLed(LedManager::EAppLed_App0, 50, 50);
        break;
    case LockManager::State_t::kState_LockCompleted:
        LOG_INF("Callback: Lock action completed");
        LedManager::getInstance().setLed(LedManager::EAppLed_App0, true);
        break;
    case LockManager::State_t::kState_UnlockInitiated:
        LOG_INF("Callback: Unlock action initiated");
        LedManager::getInstance().setLed(LedManager::EAppLed_App0, 50, 50);
        break;
    case LockManager::State_t::kState_UnlockCompleted:
        LOG_INF("Callback: Unlock action completed");
        LedManager::getInstance().setLed(LedManager::EAppLed_App0, false);
        break;
    case LockManager::State_t::kState_NotFulyLocked:
        LOG_INF("Callback: Lock not fully locked. Unexpected state");
        LedManager::getInstance().setLed(LedManager::EAppLed_App0, 10, 90);
        break;
    }
}

void AppTask::LinkButtons(ButtonManager & buttonManager)
{
    buttonManager.addCallback(FactoryResetButtonEventHandler, 0, true);
    buttonManager.addCallback(ExampleActionButtonEventHandler, 1, true);
}

void AppTask::LinkLeds(LedManager & ledManager)
{
#if CONFIG_CHIP_ENABLE_APPLICATION_STATUS_LED
    ledManager.linkLed(LedManager::EAppLed_Status, 0);
    ledManager.linkLed(LedManager::EAppLed_App0, 1);
#else
    ledManager.linkLed(LedManager::EAppLed_App0, 0);
#endif // CONFIG_CHIP_ENABLE_APPLICATION_STATUS_LED
}
```

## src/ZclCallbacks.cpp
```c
/*
 *
 *    Copyright (c) 2023-2024 Project CHIP Authors
 *    All rights reserved.
 *
 *    Licensed under the Apache License, Version 2.0 (the "License");
 *    you may not use this file except in compliance with the License.
 *    You may obtain a copy of the License at
 *
 *        http://www.apache.org/licenses/LICENSE-2.0
 *
 *    Unless required by applicable law or agreed to in writing, software
 *    distributed under the License is distributed on an "AS IS" BASIS,
 *    WITHOUT WARRANTIES OR CONDITIONS OF ANY KIND, either express or implied.
 *    See the License for the specific language governing permissions and
 *    limitations under the License.
 */

/**
 * @file
 *   This file implements the handler for data model messages.
 */

#include "AppConfig.h"
#include "LockManager.h"
#include <platform/CHIPDeviceLayer.h>

#include <app-common/zap-generated/ids/Attributes.h>
#include <app-common/zap-generated/ids/Clusters.h>
#include <app/ConcreteAttributePath.h>
#include <app/data-model/Nullable.h>
#include <lib/core/DataModelTypes.h>
#include <lib/support/logging/CHIPLogging.h>

using namespace ::chip::app::Clusters;
using namespace ::chip::DeviceLayer::Internal;
using ::chip::app::DataModel::Nullable;

void MatterPostAttributeChangeCallback(const chip::app::ConcreteAttributePath & attributePath, uint8_t type, uint16_t size,
                                       uint8_t * value)
{
    chip::ClusterId clusterId     = attributePath.mClusterId;
    chip::AttributeId attributeId = attributePath.mAttributeId;
    ChipLogProgress(Zcl, "Cluster callback: " ChipLogFormatMEI, ChipLogValueMEI(clusterId));

    if (clusterId == DoorLock::Id && attributeId == DoorLock::Attributes::LockState::Id)
    {
        DoorLock::DlLockState lockState = *(reinterpret_cast<DoorLock::DlLockState *>(value));
        ChipLogProgress(Zcl, "Door lock cluster: " ChipLogFormatMEI " state %d", ChipLogValueMEI(clusterId),
                        chip::to_underlying(lockState));
    }
}

/** @brief DoorLock Cluster Init
 *
 * This function is called when a specific cluster is initialized. It gives the
 * application an opportunity to take care of cluster initialization procedures.
 * It is called exactly once for each endpoint where cluster is present.
 *
 * @param endpoint   Ver.: always
 *
 */
void emberAfDoorLockClusterInitCallback(chip::EndpointId endpoint) {}

bool emberAfPluginDoorLockOnDoorLockCommand(chip::EndpointId endpointId, const Nullable<chip::FabricIndex> & fabricIdx,
                                            const Nullable<chip::NodeId> & nodeId, const Optional<chip::ByteSpan> & pinCode,
                                            OperationErrorEnum & err)
{
    ChipLogProgress(Zcl, "Door Lock App: Lock Command endpoint=%d", endpointId);

    return LockMgr().LockAction(AppEvent::kEventType_DeviceAction, LockManager::LOCK_ACTION, LockManager::OperationSource::kRemote,
                                endpointId, err, fabricIdx, nodeId, pinCode);
}

bool emberAfPluginDoorLockOnDoorUnlockCommand(chip::EndpointId endpointId, const Nullable<chip::FabricIndex> & fabricIdx,
                                              const Nullable<chip::NodeId> & nodeId, const Optional<chip::ByteSpan> & pinCode,
                                              OperationErrorEnum & err)
{
    ChipLogProgress(Zcl, "Door Lock App: Unlock Command endpoint=%d", endpointId);

    return LockMgr().LockAction(AppEvent::kEventType_DeviceAction, LockManager::UNLOCK_ACTION,
                                LockManager::OperationSource::kRemote, endpointId, err, fabricIdx, nodeId, pinCode);
}

bool emberAfPluginDoorLockGetCredential(chip::EndpointId endpointId, uint16_t credentialIndex, CredentialTypeEnum credentialType,
                                        EmberAfPluginDoorLockCredentialInfo & credential)
{
    return LockMgr().GetCredential(endpointId, credentialIndex, credentialType, credential);
}

bool emberAfPluginDoorLockSetCredential(chip::EndpointId endpointId, uint16_t credentialIndex, chip::FabricIndex creator,
                                        chip::FabricIndex modifier, DlCredentialStatus credentialStatus,
                                        CredentialTypeEnum credentialType, const chip::ByteSpan & credentialData)
{
    return LockMgr().SetCredential(endpointId, credentialIndex, creator, modifier, credentialStatus, credentialType,
                                   credentialData);
}

bool emberAfPluginDoorLockGetUser(chip::EndpointId endpointId, uint16_t userIndex, EmberAfPluginDoorLockUserInfo & user)
{
    return LockMgr().GetUser(endpointId, userIndex, user);
}

bool emberAfPluginDoorLockSetUser(chip::EndpointId endpointId, uint16_t userIndex, chip::FabricIndex creator,
                                  chip::FabricIndex modifier, const chip::CharSpan & userName, uint32_t uniqueId,
                                  UserStatusEnum userStatus, UserTypeEnum usertype, CredentialRuleEnum credentialRule,
                                  const CredentialStruct * credentials, size_t totalCredentials)
{

    return LockMgr().SetUser(endpointId, userIndex, creator, modifier, userName, uniqueId, userStatus, usertype, credentialRule,
                             credentials, totalCredentials);
}
```
